# iostr731 register map
Registers are 16-bit, access not given, no defined reset value unless marked. A register's access mark holds for its fields unless they carry their own. Addresses are absolute; registers are grouped by the start of their names; [hi:lo] are bit positions; {n}, {i} and the like mark numbered series; 'fields as' and 'values as' point back to an identical list.

## WDG
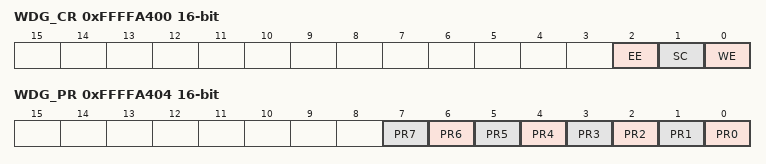
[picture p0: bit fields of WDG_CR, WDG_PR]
0xFFFFA400 WDG_CR
  [2] EE, [1] SC, [0] WE
0xFFFFA404 WDG_PR
  [n] PR{n} (n=0..7)
0xFFFFA408 WDG_VR
0xFFFFA40C WDG_CNT
0xFFFFA410 WDG_SR
  [0] EC
0xFFFFA414 WDG_MR
  [0] ECM
0xFFFFA418 WDG_KR

## WUT
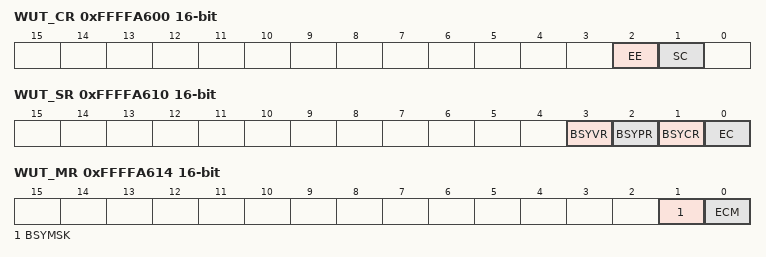
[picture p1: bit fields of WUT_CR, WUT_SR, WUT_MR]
0xFFFFA600 WUT_CR
  [2] EE, [1] SC
0xFFFFA604 WUT_PR
  [7:0] PR
0xFFFFA608 WUT_VR
0xFFFFA60C WUT_CNT
0xFFFFA610 WUT_SR
  [3] BSYVR, [2] BSYPR, [1] BSYCR, [0] EC
0xFFFFA614 WUT_MR
  [1] BSYMSK, [0] ECM

## TIM0
0xFFFFA800 TIM0_ICAR
0xFFFFA804 TIM0_ICBR
0xFFFFA808 TIM0_OCAR
0xFFFFA80C TIM0_OCBR
0xFFFFA810 TIM0_CNTR
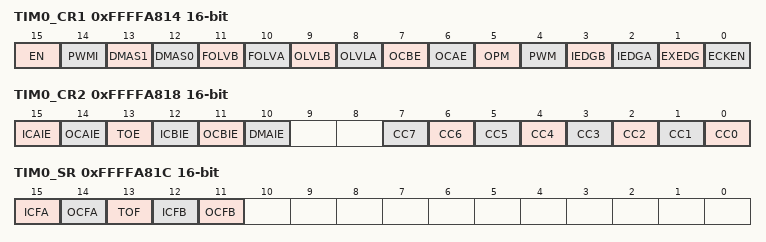
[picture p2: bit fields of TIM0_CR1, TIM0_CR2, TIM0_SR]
0xFFFFA814 TIM0_CR1
  [15] EN, [14] PWMI, [13] DMAS1, [12] DMAS0, [11] FOLVB, [10] FOLVA, [9] OLVLB, [8] OLVLA, [7] OCBE, [6] OCAE, [5] OPM, [4] PWM, [3] IEDGB, [2] IEDGA, [1] EXEDG, [0] ECKEN
0xFFFFA818 TIM0_CR2
  [15] ICAIE, [14] OCAIE, [13] TOE, [12] ICBIE, [11] OCBIE, [10] DMAIE, [n] CC{n} (n=0..7)
0xFFFFA81C TIM0_SR
  [15] ICFA, [14] OCFA, [13] TOF, [12] ICFB, [11] OCFB

## TIM1
0xFFFFAC00 TIM1_ICAR
0xFFFFAC04 TIM1_ICBR
0xFFFFAC08 TIM1_OCAR
0xFFFFAC0C TIM1_OCBR
0xFFFFAC10 TIM1_CNTR
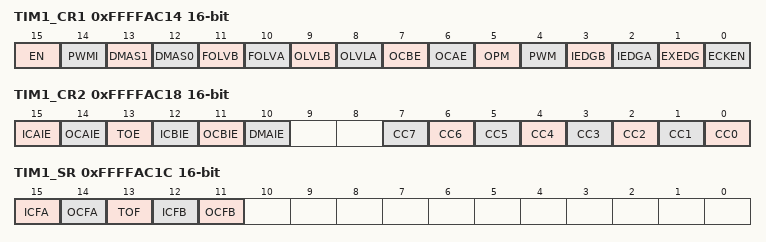
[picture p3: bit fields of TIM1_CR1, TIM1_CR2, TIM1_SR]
0xFFFFAC14 TIM1_CR1
  [15] EN, [14] PWMI, [13] DMAS1, [12] DMAS0, [11] FOLVB, [10] FOLVA, [9] OLVLB, [8] OLVLA, [7] OCBE, [6] OCAE, [5] OPM, [4] PWM, [3] IEDGB, [2] IEDGA, [1] EXEDG, [0] ECKEN
0xFFFFAC18 TIM1_CR2
  [15] ICAIE, [14] OCAIE, [13] TOE, [12] ICBIE, [11] OCBIE, [10] DMAIE, [n] CC{n} (n=0..7)
0xFFFFAC1C TIM1_SR
  [15] ICFA, [14] OCFA, [13] TOF, [12] ICFB, [11] OCFB

## TIM5
0xFFFFB000 TIM5_ICAR
0xFFFFB004 TIM5_ICBR
0xFFFFB008 TIM5_OCAR
0xFFFFB00C TIM5_OCBR
0xFFFFB010 TIM5_CNTR
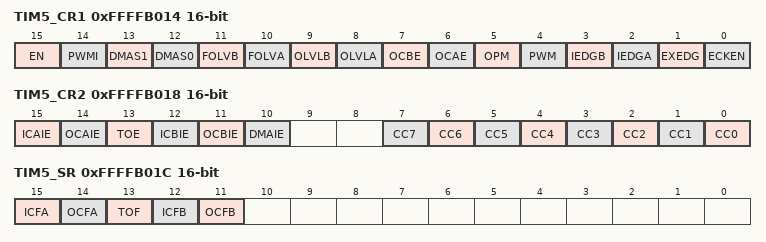
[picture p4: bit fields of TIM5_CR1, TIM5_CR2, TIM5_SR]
0xFFFFB014 TIM5_CR1
  [15] EN, [14] PWMI, [13] DMAS1, [12] DMAS0, [11] FOLVB, [10] FOLVA, [9] OLVLB, [8] OLVLA, [7] OCBE, [6] OCAE, [5] OPM, [4] PWM, [3] IEDGB, [2] IEDGA, [1] EXEDG, [0] ECKEN
0xFFFFB018 TIM5_CR2
  [15] ICAIE, [14] OCAIE, [13] TOE, [12] ICBIE, [11] OCBIE, [10] DMAIE, [n] CC{n} (n=0..7)
0xFFFFB01C TIM5_SR
  [15] ICFA, [14] OCFA, [13] TOF, [12] ICFB, [11] OCFB

## WIU
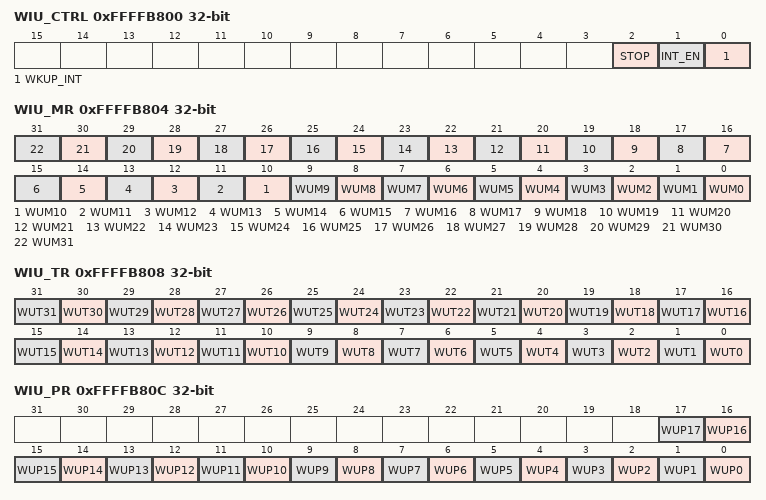
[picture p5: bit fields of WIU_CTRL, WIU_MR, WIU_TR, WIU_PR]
0xFFFFB800 WIU_CTRL 32-bit
  [2] STOP, [1] INT_EN, [0] WKUP_INT
0xFFFFB804 WIU_MR 32-bit
  [n] WUM{n} (n=0..31)
0xFFFFB808 WIU_TR 32-bit
  [n] WUT{n} (n=0..31)
0xFFFFB80C WIU_PR 32-bit
  [n] WUP{n} (n=0..17)
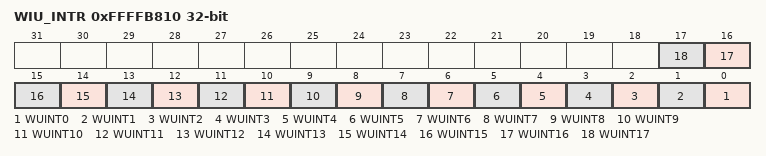
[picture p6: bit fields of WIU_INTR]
0xFFFFB810 WIU_INTR 32-bit
  [n] WUINT{n} (n=0..17)

## APB1
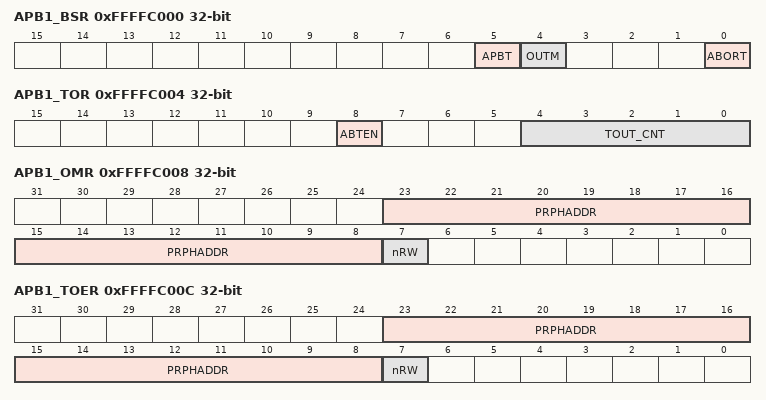
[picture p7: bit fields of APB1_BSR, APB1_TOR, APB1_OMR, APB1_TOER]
0xFFFFC000 APB1_BSR 32-bit
  [5] APBT, [4] OUTM, [0] ABORT
0xFFFFC004 APB1_TOR 32-bit
  [8] ABTEN, [4:0] TOUT_CNT
0xFFFFC008 APB1_OMR 32-bit
  [23:8] PRPHADDR, [7] nRW
0xFFFFC00C APB1_TOER 32-bit
  [23:8] PRPHADDR, [7] nRW

## CAN0
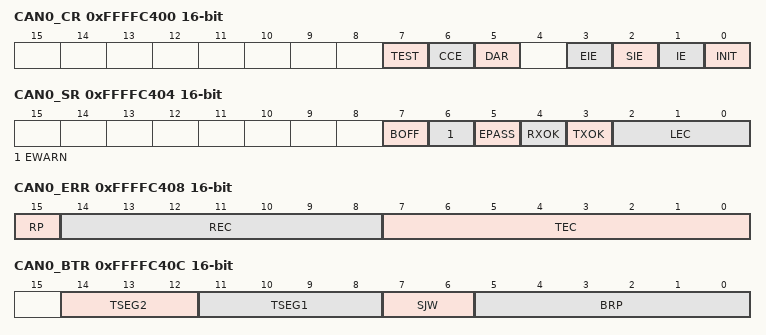
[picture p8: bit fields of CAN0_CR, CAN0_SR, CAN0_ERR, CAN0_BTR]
0xFFFFC400 CAN0_CR
  [7] TEST, [6] CCE, [5] DAR, [3] EIE, [2] SIE, [1] IE, [0] INIT
0xFFFFC404 CAN0_SR
  [7] BOFF, [6] EWARN, [5] EPASS, [4] RXOK, [3] TXOK, [2:0] LEC
0xFFFFC408 CAN0_ERR
  [15] RP, [14:8] REC, [7:0] TEC
0xFFFFC40C CAN0_BTR
  [14:12] TSEG2, [11:8] TSEG1, [7:6] SJW, [5:0] BRP
0xFFFFC410 CAN0_IDR
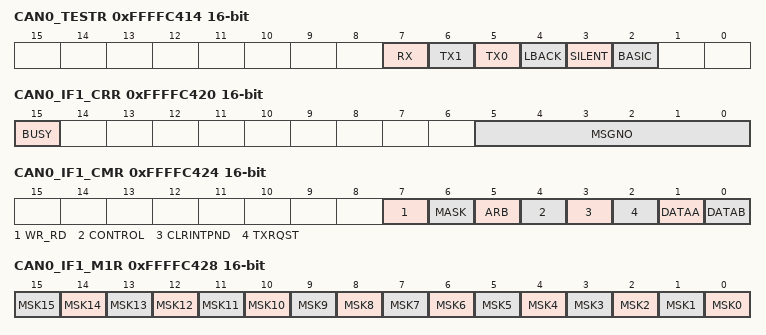
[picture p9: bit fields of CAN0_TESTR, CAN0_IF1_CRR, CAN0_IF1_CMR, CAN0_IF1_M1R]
0xFFFFC414 CAN0_TESTR
  [7] RX, [6] TX1, [5] TX0, [4] LBACK, [3] SILENT, [2] BASIC
0xFFFFC418 CAN0_BRPR
  [3:0] BRPE
0xFFFFC420 CAN0_IF1_CRR
  [15] BUSY, [5:0] MSGNO
0xFFFFC424 CAN0_IF1_CMR
  [7] WR_RD, [6] MASK, [5] ARB, [4] CONTROL, [3] CLRINTPND, [2] TXRQST, [1] DATAA, [0] DATAB
0xFFFFC428 CAN0_IF1_M1R
  [n] MSK{n} (n=0..15)
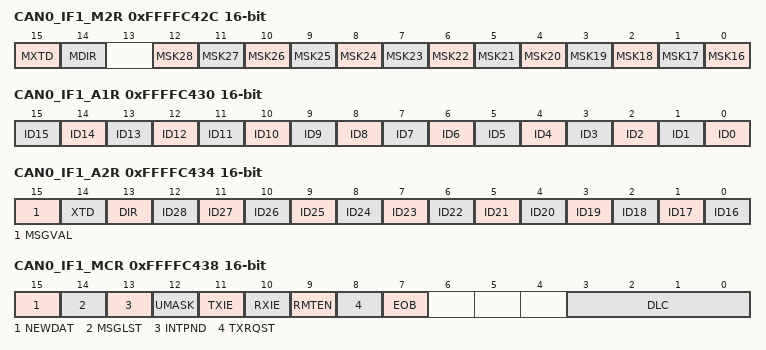
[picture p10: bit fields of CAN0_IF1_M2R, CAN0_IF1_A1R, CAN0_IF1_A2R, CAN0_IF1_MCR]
0xFFFFC42C CAN0_IF1_M2R
  [15] MXTD, [14] MDIR, [n-16] MSK{n} (n=16..28)
0xFFFFC430 CAN0_IF1_A1R
  [n] ID{n} (n=0..15)
0xFFFFC434 CAN0_IF1_A2R
  [15] MSGVAL, [14] XTD, [13] DIR, [n-16] ID{n} (n=16..28)
0xFFFFC438 CAN0_IF1_MCR
  [15] NEWDAT, [14] MSGLST, [13] INTPND, [12] UMASK, [11] TXIE, [10] RXIE, [9] RMTEN, [8] TXRQST, [7] EOB, [3:0] DLC
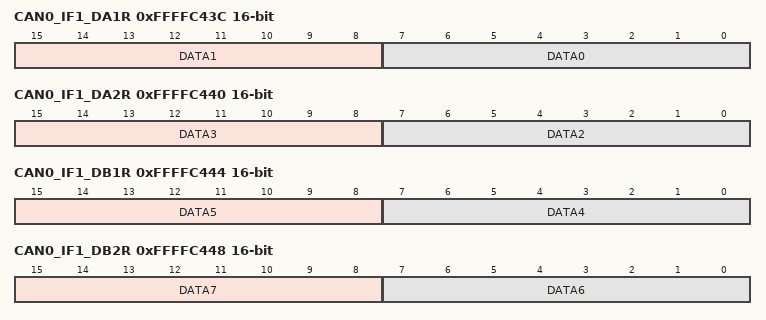
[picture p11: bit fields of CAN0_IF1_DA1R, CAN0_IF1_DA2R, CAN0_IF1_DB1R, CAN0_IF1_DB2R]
0xFFFFC43C CAN0_IF1_DA1R
  [15:8] DATA1, [7:0] DATA0
0xFFFFC440 CAN0_IF1_DA2R
  [15:8] DATA3, [7:0] DATA2
0xFFFFC444 CAN0_IF1_DB1R
  [15:8] DATA5, [7:0] DATA4
0xFFFFC448 CAN0_IF1_DB2R
  [15:8] DATA7, [7:0] DATA6
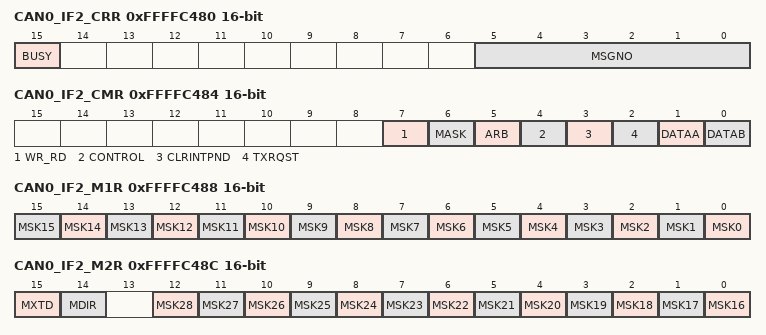
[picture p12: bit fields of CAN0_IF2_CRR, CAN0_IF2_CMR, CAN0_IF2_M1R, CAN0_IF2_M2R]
0xFFFFC480 CAN0_IF2_CRR
  [15] BUSY, [5:0] MSGNO
0xFFFFC484 CAN0_IF2_CMR
  fields as CAN0_IF1_CMR
0xFFFFC488 CAN0_IF2_M1R
  [n] MSK{n} (n=0..15)
0xFFFFC48C CAN0_IF2_M2R
  [15] MXTD, [14] MDIR, [n-16] MSK{n} (n=16..28)
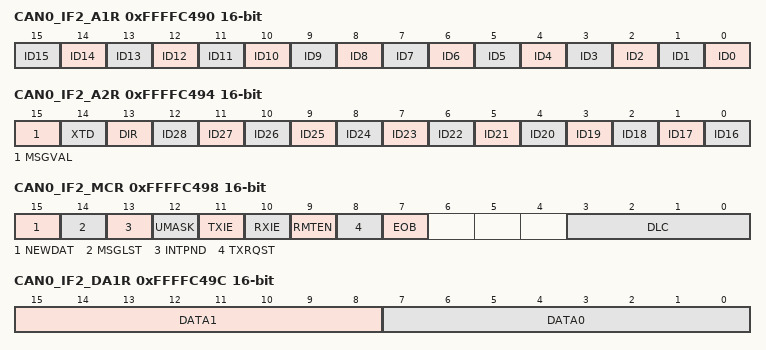
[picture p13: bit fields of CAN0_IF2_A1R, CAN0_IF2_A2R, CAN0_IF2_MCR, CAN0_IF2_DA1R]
0xFFFFC490 CAN0_IF2_A1R
  [n] ID{n} (n=0..15)
0xFFFFC494 CAN0_IF2_A2R
  [15] MSGVAL, [14] XTD, [13] DIR, [n-16] ID{n} (n=16..28)
0xFFFFC498 CAN0_IF2_MCR
  fields as CAN0_IF1_MCR
0xFFFFC49C CAN0_IF2_DA1R
  [15:8] DATA1, [7:0] DATA0
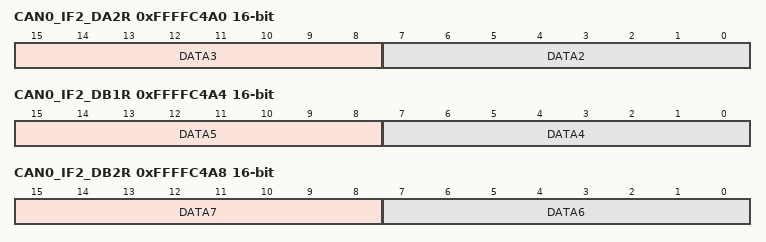
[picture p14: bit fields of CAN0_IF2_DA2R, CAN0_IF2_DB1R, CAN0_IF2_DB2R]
0xFFFFC4A0 CAN0_IF2_DA2R
  [15:8] DATA3, [7:0] DATA2
0xFFFFC4A4 CAN0_IF2_DB1R
  [15:8] DATA5, [7:0] DATA4
0xFFFFC4A8 CAN0_IF2_DB2R
  [15:8] DATA7, [7:0] DATA6
0xFFFFC500 CAN0_TXR1R 32-bit
0xFFFFC504 CAN0_TXR2R 32-bit
0xFFFFC520 CAN0_ND1R 32-bit
0xFFFFC524 CAN0_ND2R 32-bit
0xFFFFC540 CAN0_IP1R 32-bit
0xFFFFC544 CAN0_IP2R 32-bit
0xFFFFC560 CAN0_MV1R 32-bit
0xFFFFC564 CAN0_MV2R 32-bit
